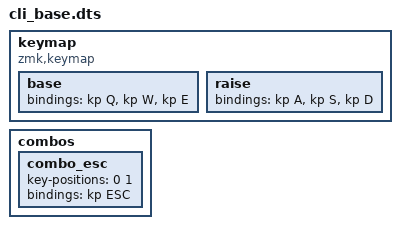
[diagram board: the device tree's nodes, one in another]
keymap {
    compatible = "zmk,keymap";
    base {
        bindings = < &kp Q &kp W &kp E >;
    };
    raise {
        bindings = < &kp A &kp S &kp D >;
    };
};

combos {
    combo_esc {
        key-positions = < 0 1 >;
        bindings = < &kp ESC >;
    };
};
